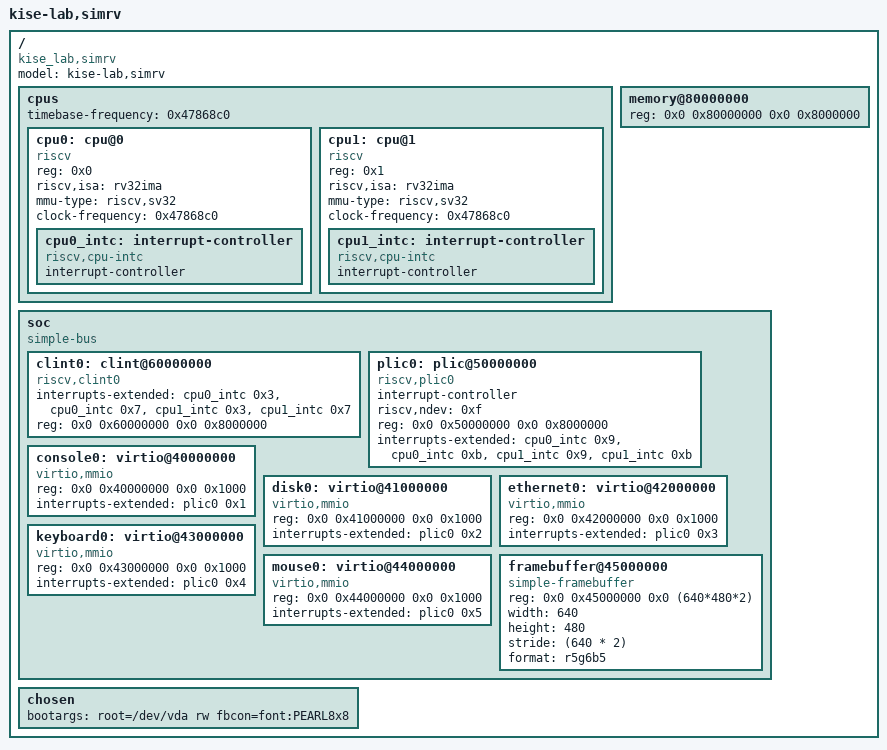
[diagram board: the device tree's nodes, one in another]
/dts-v1/;

/ {
	#address-cells = <0x2>;
	#size-cells = <0x2>;
	model = "kise-lab,simrv";
	compatible = "kise_lab,simrv";

	cpus {
		#address-cells = <0x1>;
		#size-cells = <0x0>;
		timebase-frequency = <0x47868c0>;

		cpu0: cpu@0 {
			device_type = "cpu";
			reg = <0x0>;
			status = "okay";
			compatible = "riscv";
			riscv,isa = "rv32ima";
			mmu-type = "riscv,sv32";
			clock-frequency = <0x47868c0>;

			cpu0_intc: interrupt-controller {
				#interrupt-cells = <0x1>;
				#address-cells = <0x0>;
				interrupt-controller;
				compatible = "riscv,cpu-intc";
			};
		};

		cpu1: cpu@1 {
			device_type = "cpu";
			reg = <0x1>;
			status = "okay";
			compatible = "riscv";
			riscv,isa = "rv32ima";
			mmu-type = "riscv,sv32";
			clock-frequency = <0x47868c0>;

			cpu1_intc: interrupt-controller {
				#interrupt-cells = <0x1>;
				#address-cells = <0x0>;
				interrupt-controller;
				compatible = "riscv,cpu-intc";
			};
		};
	};

	memory@80000000 {
		device_type = "memory";
		reg = <0x0 0x80000000 0x0 0x8000000>;
	};

	soc {
		#address-cells = <0x2>;
		#size-cells = <0x2>;
		compatible = "simple-bus";
		ranges;

		clint0: clint@60000000 {
			compatible = "riscv,clint0";
			interrupts-extended = <&cpu0_intc 0x3 &cpu0_intc 0x7 &cpu1_intc 0x3 &cpu1_intc 0x7>;
			reg = <0x0 0x60000000 0x0 0x8000000>;
		};

		plic0: plic@50000000 {
			#interrupt-cells = <0x1>;
			#address-cells = <0x0>;
			interrupt-controller;
			compatible = "riscv,plic0";
			riscv,ndev = <0xf>;
			reg = <0x0 0x50000000 0x0 0x8000000>;
			interrupts-extended = <&cpu0_intc 0x9 &cpu0_intc 0xb &cpu1_intc 0x9 &cpu1_intc 0xb>;
		};

		console0: virtio@40000000 {
			compatible = "virtio,mmio";
			reg = <0x0 0x40000000 0x0 0x1000>;
			interrupts-extended = <&plic0 0x1>;
		};

		disk0: virtio@41000000 {
			compatible = "virtio,mmio";
			reg = <0x0 0x41000000 0x0 0x1000>;
			interrupts-extended = <&plic0 0x2>;
		};

		ethernet0: virtio@42000000 {
			compatible = "virtio,mmio";
			reg = <0x0 0x42000000 0x0 0x1000>;
			interrupts-extended = <&plic0 0x3>;
		};

		keyboard0: virtio@43000000 {
			compatible = "virtio,mmio";
			reg = <0x0 0x43000000 0x0 0x1000>;
			interrupts-extended = <&plic0 0x4>;
		};

		mouse0: virtio@44000000 {
			compatible = "virtio,mmio";
			reg = <0x0 0x44000000 0x0 0x1000>;
			interrupts-extended = <&plic0 0x5>;
		};

		framebuffer@45000000{
			compatible = "simple-framebuffer";
			reg = <0x0 0x45000000 0x0 (640*480*2)>;
			width = <640>;
			height = <480>;
			stride = <(640 * 2)>;
			format = "r5g6b5";
			status = "okay";
		};

	};

	chosen {
		bootargs = "root=/dev/vda rw fbcon=font:PEARL8x8";
	};
};
